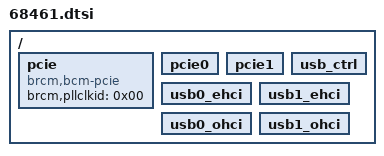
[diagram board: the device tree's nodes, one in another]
#include "6846.dtsi"

/ {
	/* pcie common */
	pcie: pcie {
		compatible = "brcm,bcm-pcie";
		device_type = "cpci";
		/* port 0,1 share same clock */
		brcm,pllclkid = <0x00>;
	};

	/* pcie core 0*/
	pcie0: pcie0 {
		#define PCIE_ID				0
		#define PCIE_SPI			60
		#define PCIE_ADDR			0x80040000
		#define PCIE_SIZE			0x0000A000
					      /*           flags    pci_addr     cpu_addr     size */
		#define PCIE_RANGE			0x02000000 0 0x90000000 0x90000000 0 0x10000000
		#include "../../ip/bcm_pcie_core.dtsi"
	};

	/* pcie core 1*/
	pcie1: pcie1 {
		#define PCIE_ID				1
		#define PCIE_SPI			61
		#define PCIE_ADDR			0x80050000
		#define PCIE_SIZE			0x0000A000
					      /*        flags,		pci_addr,   cpu_addr     size */
		#define PCIE_RANGE			0x02000000 0 0xA0000000 0xA0000000 0 0x10000000
		#include "../../ip/bcm_pcie_core.dtsi"
	};
	
	/* usb */
	usb_ctrl: usb_ctrl {
		#define USB_CTRL_ADDR       0x8000c200
		#define USB_CTRL_SIZE       0x100
		#include "../../ip/bcm_usb_ctrl.dtsi"
	};

	usb0_ehci: usb0_ehci {
		#define USB_ADDR			0x8000c300
		#define USB_SIZE			0x100
		#define USB_IRQ             125
        #define USB_PORT_ID         0
		#include "../../ip/bcm_usb_ehci.dtsi"
	};

	usb1_ehci: usb1_ehci {
		#define USB_ADDR			0x8000c500
		#define USB_SIZE			0x100
		#define USB_IRQ             123
        #define USB_PORT_ID         1
		#include "../../ip/bcm_usb_ehci.dtsi"
	};

	usb0_ohci: usb0_ohci {
		#define USB_ADDR			0x8000c400
		#define USB_SIZE			0x100
		#define USB_IRQ             124
        #define USB_PORT_ID         0
		#include "../../ip/bcm_usb_ohci.dtsi"
	};

	usb1_ohci: usb1_ohci {
		#define USB_ADDR			0x8000c600
		#define USB_SIZE			0x100
		#define USB_IRQ             122
        #define USB_PORT_ID         1
		#include "../../ip/bcm_usb_ohci.dtsi"
	};
};
